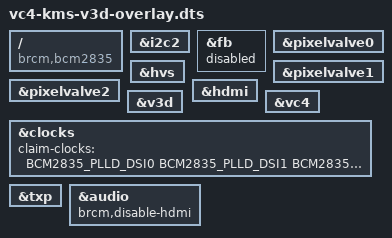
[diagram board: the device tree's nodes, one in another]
/*
 * vc4-kms-v3d-overlay.dts
 */

/dts-v1/;
/plugin/;

#include <dt-bindings/clock/bcm2835.h>

#include "cma-overlay.dts"

/ {
	compatible = "brcm,bcm2835";

	fragment@1 {
		target = <&i2c2>;
		__overlay__  {
			status = "okay";
		};
	};

	fragment@2 {
		target = <&fb>;
		__overlay__  {
			status = "disabled";
		};
	};

	fragment@3 {
		target = <&pixelvalve0>;
		__overlay__  {
			status = "okay";
		};
	};

	fragment@4 {
		target = <&pixelvalve1>;
		__overlay__  {
			status = "okay";
		};
	};

	fragment@5 {
		target = <&pixelvalve2>;
		__overlay__  {
			status = "okay";
		};
	};

	fragment@6 {
		target = <&hvs>;
		__overlay__  {
			status = "okay";
		};
	};

	fragment@7 {
		target = <&hdmi>;
		__overlay__  {
			status = "okay";
		};
	};

	fragment@8 {
		target = <&v3d>;
		__overlay__  {
			status = "okay";
		};
	};

	fragment@9 {
		target = <&vc4>;
		__overlay__  {
			status = "okay";
		};
	};

	fragment@10 {
		target = <&clocks>;
		__overlay__  {
			claim-clocks = <
				BCM2835_PLLD_DSI0
				BCM2835_PLLD_DSI1
				BCM2835_PLLH_AUX
				BCM2835_PLLH_PIX
			>;
		};
	};

	fragment@11 {
		target = <&vec>;
		__dormant__  {
			status = "okay";
		};
	};

	fragment@12 {
		target = <&txp>;
		__overlay__  {
			status = "okay";
		};
	};

	fragment@13 {
		target = <&hdmi>;
		__dormant__  {
			dmas;
		};
	};

	fragment@14 {
		target = <&audio>;
		__overlay__  {
		    brcm,disable-hdmi;
		};
	};

	__overrides__ {
		audio   = <0>,"!13";
		noaudio = <0>,"=13";
		composite = <0>, "=11";
	};
};
